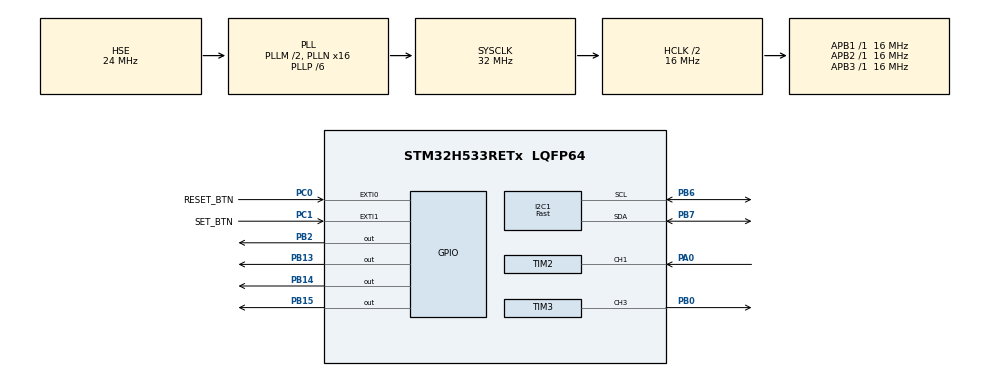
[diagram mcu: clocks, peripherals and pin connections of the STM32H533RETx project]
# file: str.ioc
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BOOTPATH.BootPathName=LEGACY
BOOTPATH.UserSelectedBootPath=LEGACY
CORTEX_M33_NS.Number-Cortex_Memory_Protection_Unit_Region0_OTP_RO_AREAS_Settings=MPU_REGION_NUMBER0
CORTEX_M33_NS.default_mode_Activation=1
CORTEX_M33_NS.userName=CORTEX_M33
I2C1.I2C_Speed_Mode=I2C_Fast
I2C1.Timing=0x0010061A
Mcu.Family=STM32H5
Mcu.Name=STM32H533RETx
Mcu.Package=LQFP64
NUCLEO-H533RE.BUTTON=1
NUCLEO-H533RE.LD4=true
NUCLEO-H533RE.VCP=true
NVIC.EXTI0_IRQn=true\:5\:0\:false\:false\:true\:true\:true\:true\:true
NVIC.EXTI13_IRQn=true\:5\:0\:false\:false\:true\:true\:false\:true\:true
NVIC.EXTI1_IRQn=true\:5\:0\:false\:false\:true\:true\:true\:true\:true
NVIC.PriorityGroup=NVIC_PRIORITYGROUP_4
NVIC.TIM2_IRQn=true\:5\:0\:false\:false\:true\:true\:true\:true\:true
NVIC.TIM6_IRQn=true\:15\:0\:false\:false\:true\:false\:false\:true\:true
NVIC.TimeBase=TIM6_IRQn
NVIC.TimeBaseIP=TIM6
PA0.Signal=S_TIM2_CH1
PA13(JTMS/SWDIO).GPIO_Label=SWDIO
PA13(JTMS/SWDIO).Mode=Serial_Wire
PA13(JTMS/SWDIO).Signal=DEBUG_JTMS-SWDIO
PA14(JTCK/SWCLK).GPIO_Label=SWCLK
PA14(JTCK/SWCLK).Mode=Serial_Wire
PA14(JTCK/SWCLK).Signal=DEBUG_JTCK-SWCLK
PA15(JTDI).GPIO_Label=JTDI
PA15(JTDI).Signal=DEBUG_JTDI
PA2.Signal=USART2_TX
PA3.Signal=USART2_RX
PB0.GPIO_ModeDefaultPP=GPIO_MODE_AF_OD
PB0.Signal=S_TIM3_CH3
PB13.Signal=GPIO_Output
PB14.Signal=GPIO_Output
PB15.Signal=GPIO_Output
PB2.Signal=GPIO_Output
PB3(JTDO/TRACESWO).GPIO_Label=SWO
PB3(JTDO/TRACESWO).Signal=DEBUG_JTDO-SWO
PB6.GPIO_Pu=GPIO_PULLUP
PB6.Mode=I2C
PB6.Signal=I2C1_SCL
PB7.GPIO_Pu=GPIO_PULLUP
PB7.Mode=I2C
PB7.Signal=I2C1_SDA
PC0.GPIO_Label=RESET_BTN
PC0.GPIO_ModeDefaultEXTI=GPIO_MODE_IT_FALLING
PC0.GPIO_PuPd=GPIO_PULLUP
PC0.Signal=GPXTI0
PC1.GPIO_Label=SET_BTN
PC1.GPIO_ModeDefaultEXTI=GPIO_MODE_IT_FALLING
PC1.GPIO_PuPd=GPIO_PULLUP
PC1.Signal=GPXTI1
PH0-OSC_IN(PH0).Mode=HSE-External-Oscillator
PH0-OSC_IN(PH0).Signal=RCC_OSC_IN
PH1-OSC_OUT(PH1).Mode=HSE-External-Oscillator
PH1-OSC_OUT(PH1).Signal=RCC_OSC_OUT
ProjectManager.HeapSize=0x200
ProjectManager.StackSize=0x400
ProjectManager.TargetToolchain=CMake
RCC.ADCFreq_Value=16000000
RCC.AHBCLKDivider=RCC_SYSCLK_DIV2
RCC.AHBFreq_Value=16000000
RCC.APB1Freq_Value=16000000
RCC.APB1TimFreq_Value=16000000
RCC.APB2Freq_Value=16000000
RCC.APB2TimFreq_Value=16000000
RCC.APB3Freq_Value=16000000
RCC.CSI_VALUE=4000000
RCC.CortexFreq_Value=16000000
RCC.EPOD_VALUE=24000000
RCC.HCLKFreq_Value=16000000
RCC.HSE_VALUE=24000000
RCC.HSI48_VALUE=48000000
RCC.HSIDiv=RCC_HSI_DIV4
RCC.HSI_VALUE=64000000
RCC.LSE_VALUE=32768
RCC.LSIRC_VALUE=32000
RCC.PLL1P=6
RCC.PLLFRACN=0
RCC.PLLM=2
RCC.PLLN=16
RCC.PLLSourceVirtual=RCC_PLL1_SOURCE_HSE
RCC.SYSCLKFreq_VALUE=32000000
RCC.SYSCLKSource=RCC_SYSCLKSOURCE_PLLCLK
RCC.USBFreq_Value=48000000
RCC.VCOOutputFreq_Value=192000000
SH.S_TIM2_CH1.0=TIM2_CH1,Input_Capture1_from_TI1
SH.S_TIM3_CH3.0=TIM3_CH3,PWM Generation3 CH3
STMicroelectronics.X-CUBE-FREERTOS.1.5.0.RTOS2CcCMSISJjRTOS2JjCore=TZIiNonIiSupported
STMicroelectronics.X-CUBE-FREERTOS.1.5.0.RTOS2CcCMSISJjRTOS2JjHeap=HeapIi1
STMicroelectronics.X-CUBE-FREERTOS.1.5.0.configENABLE_FPU=1
TIM2.Channel-Input_Capture1_from_TI1=TIM_CHANNEL_1
TIM2.ICFilter_CH1=8
TIM2.ICPolarity_CH1=TIM_INPUTCHANNELPOLARITY_FALLING
TIM2.Prescaler=15
TIM3.AutoReloadPreload=TIM_AUTORELOAD_PRELOAD_ENABLE
TIM3.Channel-PWM\ Generation3\ CH3=TIM_CHANNEL_3
TIM3.PeriodNoDither=999
TIM3.Prescaler=15
TIM3.PulseNoDither_3=500
VP_BOOTPATH_VS_BOOTPATH.Mode=BP_Activate
VP_CORTEX_M33_NS_VS_Hclk.Mode=Hclk_Mode
VP_ICACHE_VS_ICACHE.Mode=DirectMappedCache
VP_MEMORYMAP_VS_MEMORYMAP.Mode=CurAppReg
VP_NUCLEO-H533RE_VS_BSP_COMMON.Mode=COMMON
VP_PWR_VS_LPOM.Mode=PowerOptimisation
VP_PWR_VS_SECSignals.Mode=Security/Privilege
VP_STMicroelectronics.X-CUBE-FREERTOS_VS_CMSISJjRTOS2_11.2.0_1.5.0.Mode=CMSISJjRTOS2
VP_SYS_VS_tim6.Mode=TIM6
board=NUCLEO-H533RE

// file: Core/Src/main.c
/* USER CODE BEGIN Header */
/**
  ******************************************************************************
  * @file           : main.c
  * @brief          : Main program body
  ******************************************************************************
  * @attention
  *
  * Copyright (c) 2026 STMicroelectronics.
  * All rights reserved.
  *
  * This software is licensed under terms that can be found in the LICENSE file
  * in the root directory of this software component.
  * If no LICENSE file comes with this software, it is provided AS-IS.
  *
  ******************************************************************************
  */
/* USER CODE END Header */
#include "main.h"
#include "i2c.h"
#include "icache.h"
#include "tim.h"
#include "gpio.h"

/* USER CODE BEGIN Includes */
#include "my_main.h"
/* USER CODE END Includes */

COM_InitTypeDef BspCOMInit;

void SystemClock_Config(void);
static void MPU_Config(void);

int main(void)
{

  /* MCU Configuration--------------------------------------------------------*/

  /* MPU Configuration--------------------------------------------------------*/
  MPU_Config();

  /* Reset of all peripherals, Initializes the Flash interface and the Systick. */
  HAL_Init();

  /* Configure the system clock */
  SystemClock_Config();

  /* Initialize all configured peripherals */
  MX_GPIO_Init();
  MX_ICACHE_Init();
  MX_TIM2_Init();
  MX_TIM3_Init();
  MX_I2C1_Init();

  /* Init scheduler */
  /* Call init function for freertos objects (in app_freertos.c) */

  /* Initialize leds */
  BSP_LED_Init(LED_GREEN);

  /* Initialize USER push-button, will be used to trigger an interrupt each time it's pressed.*/
  // BSP_PB_Init(BUTTON_USER, BUTTON_MODE_EXTI);

  /* Initialize COM1 port (115200, 8 bits (7-bit data + 1 stop bit), no parity */
  BspCOMInit.BaudRate   = 115200;
  BspCOMInit.WordLength = COM_WORDLENGTH_8B;
  BspCOMInit.StopBits   = COM_STOPBITS_1;
  BspCOMInit.Parity     = COM_PARITY_NONE;
  BspCOMInit.HwFlowCtl  = COM_HWCONTROL_NONE;
  if (BSP_COM_Init(COM1, &BspCOMInit) != BSP_ERROR_NONE)
  {
    Error_Handler();
  }

  /* Start scheduler */

  /* We should never get here as control is now taken by the scheduler */

  /* Infinite loop */
  /* USER CODE BEGIN WHILE */
  my_main();
  while (1)
  {

    /* USER CODE END WHILE */

  }
}

void SystemClock_Config(void)
{
  RCC_OscInitTypeDef RCC_OscInitStruct = {0};
  RCC_ClkInitTypeDef RCC_ClkInitStruct = {0};

  /** Configure the main internal regulator output voltage
  */
  __HAL_PWR_VOLTAGESCALING_CONFIG(PWR_REGULATOR_VOLTAGE_SCALE3);

  while(!__HAL_PWR_GET_FLAG(PWR_FLAG_VOSRDY)) {}

  /** Initializes the RCC Oscillators according to the specified parameters
  * in the RCC_OscInitTypeDef structure.
  */
  RCC_OscInitStruct.OscillatorType = RCC_OSCILLATORTYPE_HSE;
  RCC_OscInitStruct.HSEState = RCC_HSE_ON;
  RCC_OscInitStruct.PLL.PLLState = RCC_PLL_ON;
  RCC_OscInitStruct.PLL.PLLSource = RCC_PLL1_SOURCE_HSE;
  RCC_OscInitStruct.PLL.PLLM = 2;
  RCC_OscInitStruct.PLL.PLLN = 16;
  RCC_OscInitStruct.PLL.PLLP = 6;
  RCC_OscInitStruct.PLL.PLLQ = 2;
  RCC_OscInitStruct.PLL.PLLR = 2;
  RCC_OscInitStruct.PLL.PLLRGE = RCC_PLL1_VCIRANGE_3;
  RCC_OscInitStruct.PLL.PLLVCOSEL = RCC_PLL1_VCORANGE_WIDE;
  RCC_OscInitStruct.PLL.PLLFRACN = 0;
  if (HAL_RCC_OscConfig(&RCC_OscInitStruct) != HAL_OK)
  {
    Error_Handler();
  }

  /** Initializes the CPU, AHB and APB buses clocks
  */
  RCC_ClkInitStruct.ClockType = RCC_CLOCKTYPE_HCLK|RCC_CLOCKTYPE_SYSCLK
                              |RCC_CLOCKTYPE_PCLK1|RCC_CLOCKTYPE_PCLK2
                              |RCC_CLOCKTYPE_PCLK3;
  RCC_ClkInitStruct.SYSCLKSource = RCC_SYSCLKSOURCE_PLLCLK;
  RCC_ClkInitStruct.AHBCLKDivider = RCC_SYSCLK_DIV2;
  RCC_ClkInitStruct.APB1CLKDivider = RCC_HCLK_DIV1;
  RCC_ClkInitStruct.APB2CLKDivider = RCC_HCLK_DIV1;
  RCC_ClkInitStruct.APB3CLKDivider = RCC_HCLK_DIV1;

  if (HAL_RCC_ClockConfig(&RCC_ClkInitStruct, FLASH_LATENCY_1) != HAL_OK)
  {
    Error_Handler();
  }

  /** Configure the programming delay
  */
  __HAL_FLASH_SET_PROGRAM_DELAY(FLASH_PROGRAMMING_DELAY_0);
}

 /* MPU Configuration */

void MPU_Config(void)
{
  MPU_Region_InitTypeDef MPU_InitStruct = {0};
  MPU_Attributes_InitTypeDef MPU_AttributesInit = {0};

  /* Disables the MPU */
  HAL_MPU_Disable();

  /** Initializes and configures the Region 0 and the memory to be protected
  */
  MPU_InitStruct.Enable = MPU_REGION_ENABLE;
  MPU_InitStruct.Number = MPU_REGION_NUMBER0;
  MPU_InitStruct.BaseAddress = 0x08FFF000;
  MPU_InitStruct.LimitAddress = 0x08FFFFFF;
  MPU_InitStruct.AttributesIndex = MPU_ATTRIBUTES_NUMBER0;
  MPU_InitStruct.AccessPermission = MPU_REGION_ALL_RO;
  MPU_InitStruct.DisableExec = MPU_INSTRUCTION_ACCESS_DISABLE;
  MPU_InitStruct.IsShareable = MPU_ACCESS_NOT_SHAREABLE;

  HAL_MPU_ConfigRegion(&MPU_InitStruct);

  /** Initializes and configures the Attribute 0 and the memory to be protected
  */
  MPU_AttributesInit.Number = MPU_ATTRIBUTES_NUMBER0;
  MPU_AttributesInit.Attributes = INNER_OUTER(MPU_NOT_CACHEABLE);

  HAL_MPU_ConfigMemoryAttributes(&MPU_AttributesInit);
  /* Enables the MPU */
  HAL_MPU_Enable(MPU_PRIVILEGED_DEFAULT);

}

void HAL_TIM_PeriodElapsedCallback(TIM_HandleTypeDef *htim)
{
  if (htim->Instance == TIM6)
  {
    HAL_IncTick();
  }
}

void Error_Handler(void)
{
  __disable_irq();
  while (1)
  {
  }
}
#ifdef USE_FULL_ASSERT
/**
  * @brief  Reports the name of the source file and the source line number
  *         where the assert_param error has occurred.
  * @param  file: pointer to the source file name
  * @param  line: assert_param error line source number
  * @retval None
  */
void assert_failed(uint8_t *file, uint32_t line)
{
  /* USER CODE BEGIN 6 */
  /* User can add his own implementation to report the file name and line number,
  ** example: printf("Wrong parameters value: file %s on line %d\r\n", file, line) */
  /* USER CODE END 6 */
}
#endif /* USE_FULL_ASSERT */
